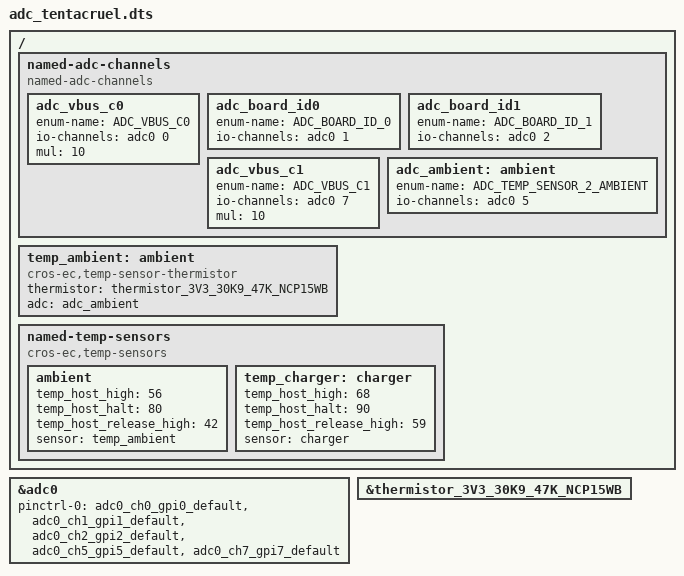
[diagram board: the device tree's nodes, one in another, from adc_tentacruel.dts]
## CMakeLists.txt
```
# Copyright 2021 The ChromiumOS Authors
# Use of this source code is governed by a BSD-style license that can be
# found in the LICENSE file.

cmake_minimum_required(VERSION 3.13.1)

find_package(Zephyr REQUIRED HINTS "${ZEPHYR_BASE}")

cros_ec_library_include_directories(include)

# Include selected EC source from the baseboard
zephyr_library_sources(
	"src/board.c"
	"src/board_chipset.c"
	"src/hibernate.c"
)

zephyr_library_sources_ifdef(CONFIG_PLATFORM_EC_USBC "src/usbc_config.c")
zephyr_library_sources_ifdef(CONFIG_PLATFORM_EC_USBC "src/usb_pd_policy.c")
zephyr_library_sources_ifdef(CONFIG_VARIANT_CORSOLA_DB_DETECTION
			     "src/variant_db_detection.c")

if(DEFINED CONFIG_BOARD_KRABBY)
	project(krabby)
	zephyr_library_sources("src/krabby/hooks.c"
			       "src/krabby/charger_workaround.c"
			       "src/krabby/ppc_krabby.c")
	zephyr_library_sources_ifdef(CONFIG_PLATFORM_EC_I2C "src/krabby/i2c.c")
	zephyr_library_sources_ifdef(CONFIG_PLATFORM_EC_USBC
				     "src/krabby/usb_pd_policy.c")
	zephyr_library_sources_ifdef(CONFIG_PLATFORM_EC_USBC
				     "src/krabby/usbc_config.c")
elseif(DEFINED CONFIG_BOARD_KINGLER)
	project(kingler)
	zephyr_library_sources_ifdef(CONFIG_PLATFORM_EC_I2C "src/kingler/i2c.c")
	zephyr_library_sources_ifdef(CONFIG_PLATFORM_EC_LED_COMMON
				     "src/kingler/led.c")
	zephyr_library_sources_ifdef(CONFIG_PLATFORM_EC_USBC
				     "src/kingler/usb_pd_policy.c")
	zephyr_library_sources_ifdef(CONFIG_PLATFORM_EC_USBC
				     "src/kingler/usbc_config.c")
	zephyr_library_sources_ifdef(CONFIG_PLATFORM_EC_BUTTONS_RUNTIME_CONFIG
				     "src/kingler/button.c")
elseif(DEFINED CONFIG_BOARD_STEELIX)
	project(steelix)
	zephyr_library_sources("src/kingler/board_steelix.c")
	zephyr_library_sources_ifdef(CONFIG_PLATFORM_EC_I2C "src/kingler/i2c.c")
	zephyr_library_sources_ifdef(CONFIG_PLATFORM_EC_LED_COMMON
				     "src/kingler/led_steelix.c")
	zephyr_library_sources_ifdef(CONFIG_PLATFORM_EC_USBC
				     "src/kingler/usb_pd_policy.c")
	zephyr_library_sources_ifdef(CONFIG_PLATFORM_EC_USBC
				     "src/kingler/usbc_config.c")

elseif(DEFINED CONFIG_BOARD_TENTACRUEL)
	project(tentacruel)
	zephyr_library_sources("src/krabby/hooks.c"
				"src/krabby/charger_workaround.c"
				"src/krabby/sensor_tentacruel.c"
				"src/krabby/temp_tentacruel.c"
				"src/krabby/ppc_tentacruel.c")
	zephyr_library_sources_ifdef(CONFIG_PLATFORM_EC_I2C "src/krabby/i2c.c")
	zephyr_library_sources_ifdef(CONFIG_PLATFORM_EC_USBC
				"src/krabby/usb_pd_policy.c")
	zephyr_library_sources_ifdef(CONFIG_PLATFORM_EC_USBC
				"src/krabby/usbc_config.c")

elseif(DEFINED CONFIG_BOARD_MAGIKARP)
	project(magikarp)
	zephyr_library_sources("src/krabby/hooks.c"
				"src/krabby/sensor_magikarp.c"
				"src/krabby/ppc_krabby.c"
				"src/krabby/keyboard_magikarp.c")
	zephyr_library_sources_ifdef(CONFIG_PLATFORM_EC_I2C "src/krabby/i2c.c")
	zephyr_library_sources_ifdef(CONFIG_PLATFORM_EC_USBC
				     "src/krabby/usb_pd_policy.c")
	zephyr_library_sources_ifdef(CONFIG_PLATFORM_EC_USBC
				     "src/krabby/usbc_config.c")

endif()
```

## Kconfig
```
# Copyright 2021 The ChromiumOS Authors
# Use of this source code is governed by a BSD-style license that can be
# found in the LICENSE file.

config BOARD_KRABBY
	bool "Google Krabby Board"
	help
	  Build Google Krabby reference board. Krabby has MediaTek MT8186 SoC
	  with ITE it81202-bx EC.

config BOARD_KINGLER
	bool "Google Kingler Board"
	help
	  Build Google Kingler reference board. Krabby has MediaTek MT8186 SoC
	  with NPCX993FA0BX EC.

config BOARD_STEELIX
	bool "Google Steelix Board"
	help
	  Build Google Steelix variant board. Steelix is a variant of Kingler
	  and has MediaTek MT8186 SoC with NPCX993FA0BX EC.

config BOARD_TENTACRUEL
	bool "Google Tentacruel Board"
	help
	  Build Google Tentacruel variant board. Tentacruel is a variant of Krabby
	  and has MediaTek MT8186 SoC with ITE it81202-bx EC.

config BOARD_MAGIKARP
	bool "Google Magikarp Board"
	help
	  Build Google Magikarp variant board. Magikarp is a variant of Krabby
	  and has MediaTek MT8186 SoC with ITE it81202-bx EC.

config VARIANT_CORSOLA_DB_DETECTION
	bool "Corsola Platform Runtime Daughter Board Detection"
	depends on PLATFORM_EC_USB_PD_TCPC_RUNTIME_CONFIG
	depends on PLATFORM_EC_USB_MUX_RUNTIME_CONFIG
	help
	  Daughter board detection for Type-C subboard or HDMI subboard. This
          includes pin configuration and driver loading.
	default y

config VARIANT_CORSOLA_USBA
	bool "Corsola Platform USB-A support"
	help
	  Support Corsola USB-A related functions. Enable this function if
	  it has USB-A ports.
        depends on PLATFORM_EC_USBC
	default y

source "Kconfig.zephyr"
```

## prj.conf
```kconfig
# Copyright 2021 The ChromiumOS Authors
# Use of this source code is governed by a BSD-style license that can be
# found in the LICENSE file.
#

# http://google3/hardware/standards/usb/
CONFIG_PLATFORM_EC_USB_PID=0x505C

# CROS EC
CONFIG_CROS_EC=y
CONFIG_PLATFORM_EC=y
CONFIG_PLATFORM_EC_SWITCH=y
CONFIG_SHIMMED_TASKS=y

# AP SoC configuration
CONFIG_AP=y
CONFIG_AP_ARM_MTK_MT8186=y

# Variant config
CONFIG_VARIANT_CORSOLA_DB_DETECTION=y

# Shell features
CONFIG_KERNEL_SHELL=y
CONFIG_SHELL_HELP=y
CONFIG_SHELL_HISTORY=y
CONFIG_SHELL_TAB=y
CONFIG_SHELL_TAB_AUTOCOMPLETION=y

# CBI
CONFIG_EEPROM=y
CONFIG_EEPROM_AT24=y
CONFIG_EEPROM_SHELL=n
CONFIG_PLATFORM_EC_BOARD_VERSION_CBI=y
CONFIG_PLATFORM_EC_CBI_EEPROM=y

# I2C
CONFIG_I2C=y

# Keyboard
CONFIG_PLATFORM_EC_KEYBOARD=y
CONFIG_PLATFORM_EC_KEYBOARD_PROTOCOL_MKBP=y
CONFIG_PLATFORM_EC_KEYBOARD_COL2_INVERTED=y

# MKBP
CONFIG_PLATFORM_EC_MKBP_EVENT=y
CONFIG_PLATFORM_EC_MKBP_INPUT_DEVICES=y
CONFIG_PLATFORM_EC_MKBP_USE_GPIO=y

# EFS2
CONFIG_PLATFORM_EC_VBOOT_EFS2=y

# USB
CONFIG_PLATFORM_EC_USB_PD_TBT_COMPAT_MODE=n
CONFIG_PLATFORM_EC_USB_PD_USB32_DRD=n
CONFIG_PLATFORM_EC_USB_PD_USB4=n
CONFIG_PLATFORM_EC_USB_PORT_POWER_DUMB_CUSTOM_HOOK=y

# USB-C
CONFIG_PLATFORM_EC_USBC=y
CONFIG_PLATFORM_EC_USBC_SS_MUX_DFP_ONLY=y
CONFIG_PLATFORM_EC_USB_PD_DPS=y
CONFIG_PLATFORM_EC_USB_PD_DP_HPD_GPIO=y
CONFIG_PLATFORM_EC_USB_PD_DP_HPD_GPIO_CUSTOM=y
CONFIG_PLATFORM_EC_USB_PD_FRS=y

# Power Seq
CONFIG_PLATFORM_EC_CHIPSET_RESUME_INIT_HOOK=y
CONFIG_PLATFORM_EC_EXTPOWER_GPIO=y
CONFIG_PLATFORM_EC_POWERSEQ=y
CONFIG_PLATFORM_EC_POWERSEQ_HOST_SLEEP=y
CONFIG_PLATFORM_EC_POWERSEQ_PP5000_CONTROL=n
CONFIG_PLATFORM_EC_POWER_SLEEP_FAILURE_DETECTION=y

# Optional features
CONFIG_FLASH_SHELL=n

# EEPROM
CONFIG_PLATFORM_EC_EEPROM_CBI_WP=y

# Host Commands
CONFIG_PLATFORM_EC_HOSTCMD=y

# Battery
CONFIG_PLATFORM_EC_BATTERY=y
CONFIG_PLATFORM_EC_BATTERY_CUT_OFF=y
CONFIG_PLATFORM_EC_BATTERY_FUEL_GAUGE=y
CONFIG_PLATFORM_EC_BATTERY_PRESENT_GPIO=y
CONFIG_PLATFORM_EC_BATTERY_SMART=y
CONFIG_PLATFORM_EC_I2C_PASSTHRU_RESTRICTED=y
CONFIG_PLATFORM_EC_I2C_VIRTUAL_BATTERY=y

# Charger
CONFIG_PLATFORM_EC_BC12_CLIENT_MODE_ONLY_PI3USB9201=y
CONFIG_PLATFORM_EC_CHARGER=y
CONFIG_PLATFORM_EC_CHARGE_MANAGER=y

# Button
CONFIG_PLATFORM_EC_CMD_BUTTON=y
CONFIG_PLATFORM_EC_POWER_BUTTON=y
CONFIG_PLATFORM_EC_VOLUME_BUTTONS=y
```

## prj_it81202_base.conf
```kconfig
# Copyright 2022 The ChromiumOS Authors
# Use of this source code is governed by a BSD-style license that can be
# found in the LICENSE file.

# Bring up options
CONFIG_SHELL_HISTORY_BUFFER=256
CONFIG_PLATFORM_EC_SYSTEM_UNLOCKED=y
CONFIG_PLATFORM_EC_BRINGUP=y

# Power Sequencing
CONFIG_PLATFORM_EC_CHIPSET_RESET_HOOK=y

# Lid Switch
CONFIG_PLATFORM_EC_LID_SWITCH=y

# Charger
CONFIG_PLATFORM_EC_CHARGE_RAMP_HW=y
CONFIG_PLATFORM_EC_CHARGER_DISCHARGE_ON_AC=y
CONFIG_PLATFORM_EC_CHARGER_DISCHARGE_ON_AC_CHARGER=y
CONFIG_PLATFORM_EC_CHARGER_RT9490=y
CONFIG_PLATFORM_EC_CHARGER_MAINTAIN_VBAT=y
CONFIG_PLATFORM_EC_CHARGER_PSYS=y
CONFIG_PLATFORM_EC_CHARGER_PSYS_READ=y
# BOARD_RS2
CONFIG_PLATFORM_EC_CHARGER_SENSE_RESISTOR=10
# BOARD_RS1
CONFIG_PLATFORM_EC_CHARGER_SENSE_RESISTOR_AC=20
CONFIG_PLATFORM_EC_CONSOLE_CMD_CHARGER_DUMP=y

# Host Commands
CONFIG_PLATFORM_EC_CONSOLE_CMD_ACCELS=y
CONFIG_PLATFORM_EC_CONSOLE_CMD_ACCEL_INFO=y
CONFIG_PLATFORM_EC_CONSOLE_CMD_CHARGER_ADC_AMON_BMON=y
CONFIG_PLATFORM_EC_CONSOLE_CMD_SYSINFO=y
CONFIG_PLATFORM_EC_HOST_COMMAND_STATUS=y

# LED
CONFIG_PLATFORM_EC_LED_DT=y

# PWM
CONFIG_PWM=y
CONFIG_PWM_SHELL=n

# Sensors
CONFIG_PLATFORM_EC_MOTIONSENSE=y
CONFIG_PLATFORM_EC_ACCEL_FIFO=y
CONFIG_PLATFORM_EC_GMR_TABLET_MODE=y
CONFIG_PLATFORM_EC_LID_ANGLE=y
CONFIG_PLATFORM_EC_LID_ANGLE_UPDATE=y
CONFIG_PLATFORM_EC_SENSOR_TIGHT_TIMESTAMPS=y
CONFIG_PLATFORM_EC_TABLET_MODE=y
CONFIG_PLATFORM_EC_TABLET_MODE_SWITCH=y
CONFIG_PLATFORM_EC_MAX_SENSOR_FREQ_MILLIHZ=100000

# Sensor Drivers
CONFIG_PLATFORM_EC_ACCEL_LIS2DW12=y
CONFIG_PLATFORM_EC_ACCELGYRO_ICM42607=y
CONFIG_PLATFORM_EC_ACCELGYRO_ICM_COMM_I2C=y

# Tasks
CONFIG_TASK_CHARGER_STACK_SIZE=1024
CONFIG_TASK_CHIPSET_STACK_SIZE=1440
CONFIG_TASK_MOTIONSENSE_STACK_SIZE=1024
CONFIG_TASK_PD_STACK_SIZE=1280

# USB-A
CONFIG_PLATFORM_EC_USBA=y

# USB-C
CONFIG_PLATFORM_EC_BC12_SINGLE_DRIVER=n
CONFIG_PLATFORM_EC_USBC_PPC_RT1739=y
CONFIG_PLATFORM_EC_USBC_PPC_SYV682C=y
CONFIG_PLATFORM_EC_USBC_PPC_SYV682X=y
CONFIG_PLATFORM_EC_USB_MUX_IT5205=y
CONFIG_PLATFORM_EC_USB_MUX_TUSB546=y
CONFIG_PLATFORM_EC_USB_MUX_VIRTUAL=y
CONFIG_PLATFORM_EC_USB_PD_DISCHARGE_PPC=y
CONFIG_PLATFORM_EC_USB_PD_FRS_PPC=y
CONFIG_PLATFORM_EC_USB_PD_LOGGING=y
CONFIG_PLATFORM_EC_USB_PD_TCPM_DRIVER_IT8XXX2=y
CONFIG_PLATFORM_EC_USB_PD_TCPM_ITE_ON_CHIP=y
CONFIG_PLATFORM_EC_USB_PD_TCPM_TCPCI=y
CONFIG_PLATFORM_EC_USB_PD_VBUS_DETECT_PPC=y
CONFIG_PLATFORM_EC_USB_PD_VBUS_MEASURE_ADC_EACH_PORT=y
CONFIG_PLATFORM_EC_USB_PD_DUAL_ROLE_AUTO_TOGGLE=n
CONFIG_PLATFORM_EC_CONFIG_USB_PD_3A_PORTS=0
CONFIG_PLATFORM_EC_USB_PD_PULLUP=1

CONFIG_PLATFORM_EC_SHA256_UNROLLED=y

# TODO(b/180980668): bring these features up
CONFIG_LTO=n
CONFIG_PLATFORM_EC_BACKLIGHT_LID=n
```

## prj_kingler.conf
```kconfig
# Copyright 2021 The Chromium OS Authors. All rights reserved.
# Use of this source code is governed by a BSD-style license that can be
# found in the LICENSE file.

# Variant config
CONFIG_BOARD_KINGLER=y

# LED
CONFIG_PLATFORM_EC_LED_PWM=y

# Keyboard
CONFIG_PLATFORM_EC_KEYBOARD_PWRBTN_ASSERTS_KSI2=y
```

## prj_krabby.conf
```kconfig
# Copyright 2021 The Chromium OS Authors.
# Use of this source code is governed by a BSD-style license that can be
# found in the LICENSE file.

# Variant config
CONFIG_BOARD_KRABBY=y

# Keyboard
CONFIG_PLATFORM_EC_KEYBOARD_PWRBTN_ASSERTS_KSI2=y
```

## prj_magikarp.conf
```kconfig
# Copyright 2022 The ChromiumOS Authors
# Use of this source code is governed by a BSD-style license that can be
# found in the LICENSE file.

# Variant config
CONFIG_BOARD_MAGIKARP=y

# USB-C
CONFIG_PLATFORM_EC_BC12_DETECT_PI3USB9201=y
CONFIG_PLATFORM_EC_USB_MUX_TUSB546=n
CONFIG_PLATFORM_EC_USB_MUX_PS8743=y
CONFIG_PLATFORM_EC_PD_MAX_POWER_MW=45000

# Keyboard
CONFIG_PLATFORM_EC_KEYBOARD_REFRESH_ROW3=y
CONFIG_PLATFORM_EC_KEYBOARD_PWRBTN_ASSERTS_KSI3=y

# Sensor
CONFIG_PLATFORM_EC_ACCELGYRO_BMI3XX=y
CONFIG_PLATFORM_EC_ACCELGYRO_BMI_COMM_I2C=y

# Temperature sensors
CONFIG_PLATFORM_EC_TEMP_SENSOR=y
CONFIG_PLATFORM_EC_THERMISTOR=y

# Battery
CONFIG_PLATFORM_EC_BATTERY_REVIVE_DISCONNECT=y
```

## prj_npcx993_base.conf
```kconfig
# Copyright 2022 The ChromiumOS Authors.
# Use of this source code is governed by a BSD-style license that can be
# found in the LICENSE file.


# Bring up options
CONFIG_PLATFORM_EC_SYSTEM_UNLOCKED=y

# Debug options and features; can be disabled to save memory or once bringup
# is complete.
CONFIG_SHELL_MINIMAL=n
CONFIG_LOG=y
CONFIG_LOG_MODE_MINIMAL=y

# ADC
CONFIG_ADC=y

# Charger
CONFIG_PLATFORM_EC_CHARGER_DISCHARGE_ON_AC=y
CONFIG_PLATFORM_EC_CHARGER_ISL9238C=y
CONFIG_PLATFORM_EC_CHARGER_PSYS=y
CONFIG_PLATFORM_EC_CHARGER_PSYS_READ=y
CONFIG_PLATFORM_EC_CHARGER_SENSE_RESISTOR=10
CONFIG_PLATFORM_EC_CHARGER_SENSE_RESISTOR_AC=20
CONFIG_PLATFORM_EC_CONSOLE_CMD_CHARGER_ADC_AMON_BMON=y

# PWM
CONFIG_PWM=y
CONFIG_PWM_SHELL=n

# LED
CONFIG_PLATFORM_EC_LED_COMMON=y
CONFIG_PLATFORM_EC_LED_ONOFF_STATES=y

# Math
CONFIG_PLATFORM_EC_MATH_UTIL=y

# Power sequencing
CONFIG_PLATFORM_EC_POWERSEQ_MT8186=y
CONFIG_PLATFORM_EC_POWERSEQ_S4=n

# Button
CONFIG_PLATFORM_EC_BUTTONS_RUNTIME_CONFIG=y

# Sensors
CONFIG_PLATFORM_EC_ACCELGYRO_BMI3XX=y
CONFIG_PLATFORM_EC_ACCELGYRO_BMI_COMM_I2C=y
CONFIG_PLATFORM_EC_ACCEL_BMA4XX=y
CONFIG_PLATFORM_EC_ACCEL_FIFO=y
CONFIG_PLATFORM_EC_CONSOLE_CMD_ACCELS=y
CONFIG_PLATFORM_EC_CONSOLE_CMD_ACCEL_INFO=y
CONFIG_PLATFORM_EC_GMR_TABLET_MODE=y
CONFIG_PLATFORM_EC_LID_ANGLE=y
CONFIG_PLATFORM_EC_LID_ANGLE_UPDATE=y
CONFIG_PLATFORM_EC_LID_SWITCH=y
CONFIG_PLATFORM_EC_MOTIONSENSE=y
CONFIG_PLATFORM_EC_SENSOR_TIGHT_TIMESTAMPS=y
CONFIG_PLATFORM_EC_TABLET_MODE=y
CONFIG_PLATFORM_EC_TABLET_MODE_SWITCH=y

# USBA
CONFIG_PLATFORM_EC_USBA=y

# USBC
CONFIG_PLATFORM_EC_BC12_DETECT_PI3USB9201=y
CONFIG_PLATFORM_EC_BC12_SINGLE_DRIVER=n
CONFIG_PLATFORM_EC_PD_POWER_SUPPLY_TURN_OFF_DELAY=15000
CONFIG_PLATFORM_EC_PD_POWER_SUPPLY_TURN_ON_DELAY=15000
CONFIG_PLATFORM_EC_USBC_PPC=y
CONFIG_PLATFORM_EC_USBC_PPC_NX20P3483=y
CONFIG_PLATFORM_EC_USBC_PPC_RT1718S=y
CONFIG_PLATFORM_EC_USB_MUX_PS8743=y
CONFIG_PLATFORM_EC_USB_MUX_VIRTUAL=y
CONFIG_PLATFORM_EC_USB_PD_DISCHARGE_PPC=y
CONFIG_PLATFORM_EC_USB_PD_FRS_TCPC=y
CONFIG_PLATFORM_EC_USB_PD_LOGGING=y
CONFIG_PLATFORM_EC_USB_PD_DEBUG_FIXED_LEVEL=y
CONFIG_PLATFORM_EC_USB_PD_DEBUG_LEVEL=2
CONFIG_PLATFORM_EC_USB_PD_TCPM_ANX7447=y
CONFIG_PLATFORM_EC_USB_PD_TCPM_ANX7447_AUX_PU_PD=y
CONFIG_PLATFORM_EC_USB_PD_TCPM_RT1718S=y
CONFIG_PLATFORM_EC_USB_PD_TCPM_SBU=y
CONFIG_PLATFORM_EC_USB_PD_VBUS_DETECT_TCPC=y
CONFIG_PLATFORM_EC_USB_PD_VBUS_MEASURE_BY_BOARD=y

# External power
CONFIG_PLATFORM_EC_BACKLIGHT_LID=n

# Keyboard
CONFIG_CROS_KB_RAW_NPCX=y
CONFIG_CROS_KB_RAW_NPCX_KSO_HIGH_DRIVE=y

CONFIG_SYSCON=y

CONFIG_PLATFORM_EC_BOARD_VERSION_GPIO=n
```

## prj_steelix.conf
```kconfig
# Copyright 2022 The ChromiumOS Authors
# Use of this source code is governed by a BSD-style license that can be
# found in the LICENSE file.

# Variant config
CONFIG_BOARD_STEELIX=y

# steelix only use D2, drop the workaround config for H1
CONFIG_PLATFORM_EC_BOARD_RESET_AFTER_POWER_ON=n

# Motion sensor
CONFIG_PLATFORM_EC_ACCEL_LIS2DW12=y
CONFIG_PLATFORM_EC_ACCELGYRO_LSM6DSM=y
CONFIG_PLATFORM_EC_DYNAMIC_MOTION_SENSOR_COUNT=y

# Keyboard
CONFIG_PLATFORM_EC_KEYBOARD_REFRESH_ROW3=y
CONFIG_PLATFORM_EC_KEYBOARD_PWRBTN_ASSERTS_KSI3=y
CONFIG_PLATFORM_EC_KEYBOARD_STRICT_DEBOUNCE=y

# USBC
CONFIG_PLATFORM_EC_PD_MAX_CURRENT_MA=3250
CONFIG_PLATFORM_EC_PD_MAX_POWER_MW=65000

# Remove bring up options for FW QUAL
CONFIG_PLATFORM_EC_SYSTEM_UNLOCKED=n

# Remove debug options and features for FW QUAL
CONFIG_LOG=n
CONFIG_LOG_MODE_MINIMAL=n
CONFIG_SHELL_MINIMAL=y
CONFIG_PLATFORM_EC_USB_PD_DEBUG_LEVEL=0

# AC_OK debounce time
CONFIG_PLATFORM_EC_EXTPOWER_DEBOUNCE_MS=800
```

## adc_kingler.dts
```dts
/* Copyright 2022 The ChromiumOS Authors
 * Use of this source code is governed by a BSD-style license that can be
 * found in the LICENSE file.
 */

/*
 * Kingler and Steelix use the same dts, take care of this when modify it.
 */

/ {
	named-adc-channels {
		compatible = "named-adc-channels";

		adc_charger_pmon_r {
			enum-name = "ADC_PSYS";
			io-channels = <&adc0 0>;
			/*
			 * ISL9238C PSYS output is 1.44 uA/W over 33K resistor.
			 */
			mul = <21043>;
		};
		adc_ec_id0 {
			enum-name = "ADC_ID_0";
			io-channels = <&adc0 1>;
		};
		adc_ec_id1 {
			enum-name = "ADC_ID_1";
			io-channels = <&adc0 2>;
		};
		adc_charger_amon_r {
			enum-name = "ADC_AMON_BMON";
			io-channels = <&adc0 3>;
			mul = <1000>;
			div = <18>;
		};
	};
};

&adc0 {
	status = "okay";
	pinctrl-0 = <&adc0_chan0_gp45
		     &adc0_chan1_gp44
		     &adc0_chan2_gp43
		     &adc0_chan3_gp42>;
	pinctrl-names = "default";
};
```

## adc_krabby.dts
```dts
/* Copyright 2021 The Chromium OS Authors. All rights reserved.
 * Use of this source code is governed by a BSD-style license that can be
 * found in the LICENSE file.
 */

/ {
	named-adc-channels {
		compatible = "named-adc-channels";

		adc_vbus_c0 {
			enum-name = "ADC_VBUS_C0";
			io-channels = <&adc0 0>;
			mul = <10>;
		};
		adc_board_id0 {
			enum-name = "ADC_BOARD_ID_0";
			io-channels = <&adc0 1>;
		};
		adc_board_id1 {
			enum-name = "ADC_BOARD_ID_1";
			io-channels = <&adc0 2>;
		};
		adc_vbus_c1 {
			enum-name = "ADC_VBUS_C1";
			io-channels = <&adc0 7>;
			mul = <10>;
		};
	};
};

&adc0 {
	status = "okay";
	pinctrl-0 = <&adc0_ch0_gpi0_default
		     &adc0_ch1_gpi1_default
		     &adc0_ch2_gpi2_default
		     &adc0_ch7_gpi7_default>;
	pinctrl-names = "default";
};
```

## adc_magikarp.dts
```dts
/* Copyright 2022 The ChromiumOS Authors
 * Use of this source code is governed by a BSD-style license that can be
 * found in the LICENSE file.
 */

#include <cros/thermistor/thermistor.dtsi>

/ {
	named-adc-channels {
		compatible = "named-adc-channels";
		adc_vbus_c0 {
			enum-name = "ADC_VBUS_C0";
			io-channels = <&adc0 0>;
			mul = <10>;
		};
		adc_board_id0 {
			enum-name = "ADC_BOARD_ID_0";
			io-channels = <&adc0 1>;
		};
		adc_board_id1 {
			enum-name = "ADC_BOARD_ID_1";
			io-channels = <&adc0 2>;
		};
		adc_vbus_c1 {
			enum-name = "ADC_VBUS_C1";
			io-channels = <&adc0 7>;
			mul = <10>;
		};
		adc_ambient: ambient {
			enum-name = "ADC_TEMP_SENSOR_2_AMBIENT";
			io-channels = <&adc0 5>;
		};
	};
};

&adc0 {
	status = "okay";
	pinctrl-0 = <&adc0_ch0_gpi0_default
		     &adc0_ch1_gpi1_default
		     &adc0_ch2_gpi2_default
		     &adc0_ch5_gpi5_default
		     &adc0_ch7_gpi7_default>;
	pinctrl-names = "default";
};

/ {
	named-temp-sensors {
		ambient {
			compatible = "cros-ec,temp-sensor-thermistor",
				     "cros-ec,temp-sensor";
			thermistor = <&thermistor_3V3_30K9_47K_NCP15WB>;
			enum-name = "TEMP_SENSOR_AMB";
			adc = <&adc_ambient>;
		};
	};
};

&thermistor_3V3_30K9_47K_NCP15WB {
	status = "okay";
};
```

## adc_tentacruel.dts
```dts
/* Copyright 2022 The ChromiumOS Authors
 * Use of this source code is governed by a BSD-style license that can be
 * found in the LICENSE file.
 */

#include <cros/thermistor/thermistor.dtsi>

/ {
	named-adc-channels {
		compatible = "named-adc-channels";
		adc_vbus_c0 {
			enum-name = "ADC_VBUS_C0";
			io-channels = <&adc0 0>;
			mul = <10>;
		};
		adc_board_id0 {
			enum-name = "ADC_BOARD_ID_0";
			io-channels = <&adc0 1>;
		};
		adc_board_id1 {
			enum-name = "ADC_BOARD_ID_1";
			io-channels = <&adc0 2>;
		};
		adc_vbus_c1 {
			enum-name = "ADC_VBUS_C1";
			io-channels = <&adc0 7>;
			mul = <10>;
		};
		adc_ambient: ambient {
			enum-name = "ADC_TEMP_SENSOR_2_AMBIENT";
			io-channels = <&adc0 5>;
		};
	};
};

&adc0 {
	status = "okay";
	pinctrl-0 = <&adc0_ch0_gpi0_default
		     &adc0_ch1_gpi1_default
		     &adc0_ch2_gpi2_default
		     &adc0_ch5_gpi5_default
		     &adc0_ch7_gpi7_default>;
	pinctrl-names = "default";
};

/ {
	temp_ambient: ambient {
		compatible = "cros-ec,temp-sensor-thermistor";
		thermistor = <&thermistor_3V3_30K9_47K_NCP15WB>;
		adc = <&adc_ambient>;
	};

	named-temp-sensors {
		compatible = "cros-ec,temp-sensors";
		ambient {
			temp_host_high = <56>;
			temp_host_halt = <80>;
			temp_host_release_high = <42>;
			sensor = <&temp_ambient>;
		};
		temp_charger: charger {
			temp_host_high = <68>;
			temp_host_halt = <90>;
			temp_host_release_high = <59>;
			sensor = <&charger>;
		};
	};
};

&thermistor_3V3_30K9_47K_NCP15WB {
	status = "okay";
};
```

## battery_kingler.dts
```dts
/* Copyright 2021 The Chromium OS Authors. All rights reserved.
 * Use of this source code is governed by a BSD-style license that can be
 * found in the LICENSE file.
 */

/ {
	batteries {
		default_battery: smp_l20m3pg2 {
			compatible = "smp,l20m3pg2";
		};
		lgc_l20l3pg2 {
			compatible = "lgc,l20l3pg2";
		};
	};
};
```

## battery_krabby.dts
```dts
/* Copyright 2021 The ChromiumOS Authors
 * Use of this source code is governed by a BSD-style license that can be
 * found in the LICENSE file.
 */

/ {
	batteries {
		default_battery: c235 {
			compatible = "celxpert,c235-41", "battery-smart";
		};
	};
};
```

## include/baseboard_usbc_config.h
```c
/* Copyright 2021 The ChromiumOS Authors
 * Use of this source code is governed by a BSD-style license that can be
 * found in the LICENSE file.
 */

/* Corsola daughter board detection */

#ifndef __CROS_EC_BASEBOARD_USBC_CONFIG_H
#define __CROS_EC_BASEBOARD_USBC_CONFIG_H

#include "gpio.h"

#ifdef CONFIG_PLATFORM_EC_USB_PD_TCPM_RT1718S
#define GPIO_EN_USB_C1_SINK RT1718S_GPIO1
#define GPIO_EN_USB_C1_SOURCE RT1718S_GPIO2
#define GPIO_EN_USB_C1_FRS RT1718S_GPIO3
#endif

void ppc_interrupt(enum gpio_signal signal);
void ccd_interrupt(enum gpio_signal signal);
void hdmi_hpd_interrupt(enum gpio_signal signal);
void ps185_hdmi_hpd_mux_set(void);
int corsola_is_dp_muxable(int port);

/* USB-A ports */
enum usba_port { USBA_PORT_A0 = 0, USBA_PORT_COUNT };

/* USB-C ports */
enum usbc_port { USBC_PORT_C0 = 0, USBC_PORT_C1, USBC_PORT_COUNT };
BUILD_ASSERT(USBC_PORT_COUNT == CONFIG_USB_PD_PORT_MAX_COUNT);

/**
 * Is the port fine to be muxed its DisplayPort lines?
 *
 * Only one port can be muxed to DisplayPort at a time.
 *
 * @param port	Port number of TCPC.
 * @return	1 is fine; 0 is bad as other port is already muxed;
 */
int corsola_is_dp_muxable(int port);

#endif /* __CROS_EC_BASEBOARD_USBC_CONFIG_H */
```

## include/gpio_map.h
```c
/* Copyright 2021 The Chromium OS Authors. All rights reserved.
 * Use of this source code is governed by a BSD-style license that can be
 * found in the LICENSE file.
 */

#ifndef __ZEPHYR_GPIO_MAP_H
#define __ZEPHYR_GPIO_MAP_H

#include <zephyr/devicetree.h>
#include <gpio_signal.h>

#define GPIO_ENTERING_RW GPIO_UNIMPLEMENTED

#ifdef CONFIG_PLATFORM_EC_USB_PD_TCPM_RT1718S
#define GPIO_EN_USB_C1_SINK RT1718S_GPIO1
#define GPIO_EN_USB_C1_SOURCE RT1718S_GPIO2
#define GPIO_EN_USB_C1_FRS RT1718S_GPIO3
#endif

#endif /* __ZEPHYR_GPIO_MAP_H */
```

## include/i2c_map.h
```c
/* Copyright 2021 The Chromium OS Authors. All rights reserved.
 * Use of this source code is governed by a BSD-style license that can be
 * found in the LICENSE file.
 */

#ifndef __ZEPHYR_I2C_MAP_H
#define __ZEPHYR_I2C_MAP_H

#include <zephyr/devicetree.h>

#include "i2c/i2c.h"

#endif /* __ZEPHYR_I2C_MAP_H */
```

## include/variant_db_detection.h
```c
/* Copyright 2021 The ChromiumOS Authors
 * Use of this source code is governed by a BSD-style license that can be
 * found in the LICENSE file.
 */

/* Corsola daughter board detection */

#ifndef __CROS_EC_CORSOLA_DB_DETECTION_H
#define __CROS_EC_CORSOLA_DB_DETECTION_H

enum corsola_db_type {
	CORSOLA_DB_UNINIT = -1,
	CORSOLA_DB_NONE,
	CORSOLA_DB_TYPEC,
	CORSOLA_DB_HDMI,
	CORSOLA_DB_COUNT,
};

#ifdef CONFIG_VARIANT_CORSOLA_DB_DETECTION
/*
 * Get the connected daughterboard type.
 *
 * @return		The daughterboard type.
 */
enum corsola_db_type corsola_get_db_type(void);
#else
inline enum corsola_db_type corsola_get_db_type(void)
{
	return CORSOLA_DB_NONE;
};
#endif /* CONFIG_VARIANT_CORSOLA_DB_DETECTION */

/* return the adjusted port count for board overridden usbc/charger functions.
 */
uint8_t board_get_adjusted_usb_pd_port_count(void);

#endif /* __CROS_EC_CORSOLA_DB_DETECTION_H */
```

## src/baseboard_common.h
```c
/* Copyright 2021 The Chromium OS Authors. All rights reserved.
 * Use of this source code is governed by a BSD-style license that can be
 * found in the LICENSE file.
 */

/* Corsola baseboard-specific onfiguration common to ECOS and Zephyr */

#ifndef __CROS_EC_BASEBOARD_COMMON_H
#define __CROS_EC_BASEBOARD_COMMON_H

#ifndef __ASSEMBLER__

#include "gpio_signal.h"

/**
 * board_get_version() - Get the board version
 *
 * Read the ADC to obtain the board version
 *
 * @return board version in the range 0 to 14 inclusive
 */
int board_get_version(void);

void ppc_interrupt(enum gpio_signal signal);
void bc12_interrupt(enum gpio_signal signal);
void x_ec_interrupt(enum gpio_signal signal);

#endif /* !__ASSEMBLER__ */
#endif /* __CROS_EC_BASEBOARD_COMMON_H */
```

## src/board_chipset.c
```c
/* Copyright 2021 The ChromiumOS Authors
 * Use of this source code is governed by a BSD-style license that can be
 * found in the LICENSE file.
 */

/* Corsola baseboard-chipset specific configuration */

#include <zephyr/init.h>
#include <ap_power/ap_power.h>
#include <zephyr/drivers/gpio.h>
#include "gpio.h"

static void board_backlight_handler(struct ap_power_ev_callback *cb,
				    struct ap_power_ev_data data)
{
	int value;

	switch (data.event) {
	default:
		return;

	case AP_POWER_RESUME:
		/* Called on AP S3 -> S0 transition */
		value = 1;
		break;

	case AP_POWER_SUSPEND:
		/* Called on AP S0 -> S3 transition */
		value = 0;
		break;
	}
	gpio_pin_set_dt(GPIO_DT_FROM_NODELABEL(gpio_ec_bl_en_od), value);
}

static int install_backlight_handler(const struct device *unused)
{
	static struct ap_power_ev_callback cb;

	/*
	 * Add a callback for suspend/resume to
	 * control the keyboard backlight.
	 */
	ap_power_ev_init_callback(&cb, board_backlight_handler,
				  AP_POWER_RESUME | AP_POWER_SUSPEND);
	ap_power_ev_add_callback(&cb);
	return 0;
}

SYS_INIT(install_backlight_handler, APPLICATION, 1);
```

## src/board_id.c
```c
/* Copyright 2021 The Chromium OS Authors. All rights reserved.
 * Use of this source code is governed by a BSD-style license that can be
 * found in the LICENSE file.
 */

#include "adc.h"
#include "common.h"
#include "console.h"
#include "gpio.h"
#include "hooks.h"
#include "timer.h"
#include "util.h"

/**
 * Conversion based on following table:
 *
 * ID | Rp   | Rd   | Voltage
 *    | kOhm | kOhm | mV
 * ---+------+------+--------
 *  0 | 51.1 |  2.2 | 136.2
 *  1 | 51.1 | 6.81 | 388.1
 *  2 | 51.1 |   11 | 584.5
 *  3 | 57.6 |   18 | 785.7
 *  4 | 51.1 |   22 | 993.2
 *  5 | 51.1 |   30 | 1220.7
 *  6 | 51.1 | 39.2 | 1432.6
 *  7 |   56 |   56 | 1650.0
 *  8 |   47 | 61.9 | 1875.8
 *  9 |   47 | 80.6 | 2084.5
 * 10 |   56 |  124 | 2273.3
 * 11 | 51.1 |  150 | 2461.5
 * 12 |   47 |  200 | 2672.1
 * 13 |   47 |  330 | 2888.6
 * 14 |   47 |  680 | 3086.7
 */
const static int voltage_map[] = {
	136,
	388,
	584,
	785,
	993,
	1220,
	1432,
	1650,
	1875,
	2084,
	2273,
	2461,
	2672,
	2888,
	3086,
};

const int threshold_mv = 100;

/**
 * Convert ADC value to board id using the voltage table above.
 *
 * @param ch	ADC channel to read, usually ADC_BOARD_ID_0 or ADC_BOARD_ID_1.
 *
 * @return	a non-negative board id, or negative value if error.
 */
static int adc_value_to_numeric_id(enum adc_channel ch)
{
	int mv;

	gpio_set_level(GPIO_EN_EC_ID_ODL, 0);
	/* Wait to allow cap charge */
	msleep(10);

	mv = adc_read_channel(ch);
	if (mv == ADC_READ_ERROR)
		mv = adc_read_channel(ch);

	gpio_set_level(GPIO_EN_EC_ID_ODL, 1);

	if (mv == ADC_READ_ERROR)
		return -EC_ERROR_UNKNOWN;

	for (int i = 0; i < ARRAY_SIZE(voltage_map); i++) {
		if (IN_RANGE(mv, voltage_map[i] - threshold_mv,
			     voltage_map[i] + threshold_mv))
			return i;
	}

	return -EC_ERROR_UNKNOWN;
}

static int version = -1;

/* b/163963220: Cache ADC value before board_hibernate_late() reads it */
static void board_version_init(void)
{
	version = adc_value_to_numeric_id(ADC_BOARD_ID_0);
	if (version < 0) {
		ccprints("WARN:BOARD_ID_0");
		ccprints("Assuming board id = 0");

		version = 0;
	}
}
DECLARE_HOOK(HOOK_INIT, board_version_init, HOOK_PRIO_INIT_ADC + 1);

__override int board_get_version(void)
{
	return version;
}
```

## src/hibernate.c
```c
/* Copyright 2021 The Chromium OS Authors. All rights reserved.
 * Use of this source code is governed by a BSD-style license that can be
 * found in the LICENSE file.
 */
#include <zephyr/drivers/gpio.h>

#include "charger.h"
#include "driver/charger/isl923x_public.h"
#include "system.h"

/* Corsola board specific hibernate implementation */
__override void board_hibernate(void)
{
#ifdef CONFIG_CHARGER_ISL9238C
	isl9238c_hibernate(CHARGER_SOLO);
#endif
}

__override void board_hibernate_late(void)
{
	gpio_pin_set_dt(GPIO_DT_FROM_NODELABEL(gpio_en_ulp), 1);
}
```

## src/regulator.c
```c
/* Copyright 2021 The Chromium OS Authors. All rights reserved.
 * Use of this source code is governed by a BSD-style license that can be
 * found in the LICENSE file.
 */

#include "common.h"
#include "bc12/mt6360_public.h"

/* SD Card */
int board_regulator_get_info(uint32_t index, char *name, uint16_t *num_voltages,
			     uint16_t *voltages_mv)
{
	enum mt6360_regulator_id id = index;

	return mt6360_regulator_get_info(id, name, num_voltages, voltages_mv);
}

int board_regulator_enable(uint32_t index, uint8_t enable)
{
	enum mt6360_regulator_id id = index;

	return mt6360_regulator_enable(id, enable);
}

int board_regulator_is_enabled(uint32_t index, uint8_t *enabled)
{
	enum mt6360_regulator_id id = index;

	return mt6360_regulator_is_enabled(id, enabled);
}

int board_regulator_set_voltage(uint32_t index, uint32_t min_mv,
				uint32_t max_mv)
{
	enum mt6360_regulator_id id = index;

	return mt6360_regulator_set_voltage(id, min_mv, max_mv);
}

int board_regulator_get_voltage(uint32_t index, uint32_t *voltage_mv)
{
	enum mt6360_regulator_id id = index;

	return mt6360_regulator_get_voltage(id, voltage_mv);
}
```

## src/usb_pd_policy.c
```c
/* Copyright 2021 The ChromiumOS Authors
 * Use of this source code is governed by a BSD-style license that can be
 * found in the LICENSE file.
 */

#include "atomic.h"
#include "console.h"
#include "chipset.h"
#include "hooks.h"
#include "timer.h"
#include "typec_control.h"
#include "usb_dp_alt_mode.h"
#include "usb_mux.h"
#include "usb_pd.h"
#include "usbc_ppc.h"

#include "baseboard_usbc_config.h"

#if CONFIG_USB_PD_3A_PORTS != 1
#error Corsola reference must have at least one 3.0 A port
#endif

#define CPRINTS(format, args...) cprints(CC_USBPD, format, ##args)
#define CPRINTF(format, args...) cprintf(CC_USBPD, format, ##args)

static int active_aux_port = -1;

int pd_check_vconn_swap(int port)
{
	/* Allow Vconn swap if AP is on. */
	return chipset_in_state(CHIPSET_STATE_SUSPEND | CHIPSET_STATE_ON);
}

static void set_dp_aux_path_sel(int port)
{
	gpio_pin_set_dt(GPIO_DT_FROM_NODELABEL(dp_aux_path_sel), port);
	CPRINTS("Set DP_AUX_PATH_SEL: %d", port);
}

int svdm_get_hpd_gpio(int port)
{
	/* HPD is low active, inverse the result */
	return !gpio_pin_get_dt(GPIO_DT_FROM_NODELABEL(ec_ap_dp_hpd_odl));
}

static void reset_aux_deferred(void)
{
	if (active_aux_port == -1)
		/* reset to 1 for lower power consumption. */
		set_dp_aux_path_sel(1);
}
DECLARE_DEFERRED(reset_aux_deferred);

void svdm_set_hpd_gpio(int port, int en)
{
	/*
	 * HPD is low active, inverse the en.
	 *
	 * Implement FCFS policy:
	 * 1) Enable hpd if no active port.
	 * 2) Disable hpd if active port is the given port.
	 */
	if (en && active_aux_port < 0) {
		gpio_pin_set_dt(GPIO_DT_FROM_NODELABEL(ec_ap_dp_hpd_odl), 0);
		active_aux_port = port;
		hook_call_deferred(&reset_aux_deferred_data, -1);
	}

	if (!en && active_aux_port == port) {
		gpio_pin_set_dt(GPIO_DT_FROM_NODELABEL(ec_ap_dp_hpd_odl), 1);
		active_aux_port = -1;
		/*
		 * This might be a HPD debounce to send a HPD IRQ (500us), so
		 * do not reset the aux path immediately. Defer this call and
		 * re-check if this is a real disable.
		 */
		hook_call_deferred(&reset_aux_deferred_data, 1 * MSEC);
	}
}

__override int svdm_dp_config(int port, uint32_t *payload)
{
	int opos = pd_alt_mode(port, TCPCI_MSG_SOP, USB_SID_DISPLAYPORT);
	uint8_t pin_mode = get_dp_pin_mode(port);
	mux_state_t mux_mode = svdm_dp_get_mux_mode(port);
	int mf_pref = PD_VDO_DPSTS_MF_PREF(dp_status[port]);

	if (!pin_mode) {
		return 0;
	}

	CPRINTS("pin_mode: %x, mf: %d, mux: %d", pin_mode, mf_pref, mux_mode);
	/*
	 * Defer setting the usb_mux until HPD goes high, svdm_dp_attention().
	 * The AP only supports one DP phy. An external DP mux switches between
	 * the two ports. Should switch those muxes when it is really used,
	 * i.e. HPD high; otherwise, the real use case is preempted, like:
	 *  (1) plug a dongle without monitor connected to port-0,
	 *  (2) plug a dongle without monitor connected to port-1,
	 *  (3) plug a monitor to the port-1 dongle.
	 */

	payload[0] =
		VDO(USB_SID_DISPLAYPORT, 1, CMD_DP_CONFIG | VDO_OPOS(opos));
	payload[1] = VDO_DP_CFG(pin_mode, /* pin mode */
				1, /* DPv1.3 signaling */
				2); /* UFP connected */
	return 2;
};

__override void svdm_dp_post_config(int port)
{
	mux_state_t mux_mode = svdm_dp_get_mux_mode(port);

	typec_set_sbu(port, true);

	/*
	 * Prior to post-config, the mux will be reset to safe mode, and this
	 * will break mux config and aux path config we did in the first DP
	 * status command. Only enable this if the port is the current aux-port.
	 */
	if (port == active_aux_port) {
		usb_mux_set(port, mux_mode, USB_SWITCH_CONNECT,
			    polarity_rm_dts(pd_get_polarity(port)));
		usb_mux_hpd_update(port, USB_PD_MUX_HPD_LVL |
						 USB_PD_MUX_HPD_IRQ_DEASSERTED);
	}

	dp_flags[port] |= DP_FLAGS_DP_ON;
}

int corsola_is_dp_muxable(int port)
{
	int i;

	for (i = 0; i < board_get_usb_pd_port_count(); i++) {
		if (i != port) {
			if (usb_mux_get(i) & USB_PD_MUX_DP_ENABLED) {
				return 0;
			}
		}
	}

	return 1;
}

__override int svdm_dp_attention(int port, uint32_t *payload)
{
	int lvl = PD_VDO_DPSTS_HPD_LVL(payload[1]);
	int irq = PD_VDO_DPSTS_HPD_IRQ(payload[1]);
#ifdef CONFIG_USB_PD_DP_HPD_GPIO
	int cur_lvl = svdm_get_hpd_gpio(port);
#endif /* CONFIG_USB_PD_DP_HPD_GPIO */
	mux_state_t mux_state;

	dp_status[port] = payload[1];

	if (!corsola_is_dp_muxable(port)) {
		/* TODO(waihong): Info user? */
		CPRINTS("p%d: The other port is already muxed.", port);
		return 0; /* nak */
	}

	if (lvl) {
		set_dp_aux_path_sel(port);

		usb_mux_set(port, USB_PD_MUX_DOCK, USB_SWITCH_CONNECT,
			    polarity_rm_dts(pd_get_polarity(port)));
	} else {
		usb_mux_set(port, USB_PD_MUX_USB_ENABLED, USB_SWITCH_CONNECT,
			    polarity_rm_dts(pd_get_polarity(port)));
	}

	if (chipset_in_state(CHIPSET_STATE_ANY_SUSPEND) && (irq || lvl)) {
		/*
		 * Wake up the AP.  IRQ or level high indicates a DP sink is now
		 * present.
		 */
		if (IS_ENABLED(CONFIG_MKBP_EVENT)) {
			pd_notify_dp_alt_mode_entry(port);
		}
	}

#ifdef CONFIG_USB_PD_DP_HPD_GPIO
	if (irq && !lvl) {
		/*
		 * IRQ can only be generated when the level is high, because
		 * the IRQ is signaled by a short low pulse from the high level.
		 */
		CPRINTF("ERR:HPD:IRQ&LOW\n");
		return 0; /* nak */
	}

	if (irq && cur_lvl) {
		uint64_t now = get_time().val;
		/* wait for the minimum spacing between IRQ_HPD if needed */
		if (now < svdm_hpd_deadline[port]) {
			usleep(svdm_hpd_deadline[port] - now);
		}

		/* generate IRQ_HPD pulse */
		svdm_set_hpd_gpio(port, 0);
		/*
		 * b/171172053#comment14: since the HPD_DSTREAM_DEBOUNCE_IRQ is
		 * very short (500us), we can use udelay instead of usleep for
		 * more stable pulse period.
		 */
		udelay(HPD_DSTREAM_DEBOUNCE_IRQ);
		svdm_set_hpd_gpio(port, 1);
	} else {
		svdm_set_hpd_gpio(port, lvl);
	}

	/* set the minimum time delay (2ms) for the next HPD IRQ */
	svdm_hpd_deadline[port] = get_time().val + HPD_USTREAM_DEBOUNCE_LVL;
#endif /* CONFIG_USB_PD_DP_HPD_GPIO */

	mux_state = (lvl ? USB_PD_MUX_HPD_LVL : USB_PD_MUX_HPD_LVL_DEASSERTED) |
		    (irq ? USB_PD_MUX_HPD_IRQ : USB_PD_MUX_HPD_IRQ_DEASSERTED);
	usb_mux_hpd_update(port, mux_state);

#ifdef USB_PD_PORT_TCPC_MST
	if (port == USB_PD_PORT_TCPC_MST) {
		baseboard_mst_enable_control(port, lvl);
	}
#endif

	/* ack */
	return 1;
}
```

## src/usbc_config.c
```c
/* Copyright 2021 The ChromiumOS Authors
 * Use of this source code is governed by a BSD-style license that can be
 * found in the LICENSE file.
 */

/* Corsola baseboard-specific USB-C configuration */

#include <zephyr/drivers/gpio.h>
#include <ap_power/ap_power.h>

#include "adc.h"
#include "baseboard_usbc_config.h"
#include "button.h"
#include "charger.h"
#include "charge_state_v2.h"
#include "console.h"
#include "ec_commands.h"
#include "extpower.h"
#include "gpio/gpio_int.h"
#include "hooks.h"
#include "i2c.h"
#include "lid_switch.h"
#include "task.h"
#include "ppc/syv682x_public.h"
#include "power.h"
#include "power_button.h"
#include "spi.h"
#include "switch.h"
#include "tablet_mode.h"
#include "uart.h"
#include "usb_charge.h"
#include "usb_mux.h"
#include "usb_pd_tcpm.h"
#include "usb_tc_sm.h"
#include "usbc/usb_muxes.h"
#include "usbc_ppc.h"

#include "variant_db_detection.h"

#define CPRINTS(format, args...) cprints(CC_SYSTEM, format, ##args)
#define CPRINTF(format, args...) cprintf(CC_SYSTEM, format, ##args)

/* a flag for indicating the tasks are inited. */
static bool tasks_inited;

/* Baseboard */
static void baseboard_init(void)
{
#ifdef CONFIG_VARIANT_CORSOLA_USBA
	gpio_enable_dt_interrupt(GPIO_INT_FROM_NODELABEL(int_usba));
#endif
	/* If CCD mode has enabled before init, force the ccd_interrupt. */
	if (!gpio_pin_get_dt(GPIO_DT_FROM_NODELABEL(gpio_ccd_mode_odl))) {
		ccd_interrupt(GPIO_CCD_MODE_ODL);
	}
	gpio_enable_dt_interrupt(GPIO_INT_FROM_NODELABEL(int_ccd_mode_odl));
}
DECLARE_HOOK(HOOK_INIT, baseboard_init, HOOK_PRIO_PRE_DEFAULT);

__override uint8_t board_get_usb_pd_port_count(void)
{
	/* This function returns the PORT_COUNT+1 when HDMI db is connected.
	 * This is a trick to ensure the usb_mux_set being set properley.
	 * HDMI display functions using the USB virtual mux to * communicate
	 * with the DP bridge.
	 */
	if (corsola_get_db_type() == CORSOLA_DB_HDMI) {
		if (tasks_inited) {
			return CONFIG_USB_PD_PORT_MAX_COUNT;
		} else {
			return CONFIG_USB_PD_PORT_MAX_COUNT - 1;
		}
	} else if (corsola_get_db_type() == CORSOLA_DB_NONE) {
		return CONFIG_USB_PD_PORT_MAX_COUNT - 1;
	}

	return CONFIG_USB_PD_PORT_MAX_COUNT;
}

uint8_t board_get_adjusted_usb_pd_port_count(void)
{
	if (corsola_get_db_type() == CORSOLA_DB_TYPEC) {
		return CONFIG_USB_PD_PORT_MAX_COUNT;
	} else {
		return CONFIG_USB_PD_PORT_MAX_COUNT - 1;
	}
}

/* USB-A */
void usb_a0_interrupt(enum gpio_signal signal)
{
	enum usb_charge_mode mode = gpio_pin_get_dt(GPIO_DT_FROM_NODELABEL(
					    gpio_ap_xhci_init_done)) ?
					    USB_CHARGE_MODE_ENABLED :
					    USB_CHARGE_MODE_DISABLED;

	const int xhci_stat = gpio_get_level(signal);

	for (int i = 0; i < USB_PORT_COUNT; i++) {
		usb_charge_set_mode(i, mode, USB_ALLOW_SUSPEND_CHARGE);
	}

	for (int i = 0; i < CONFIG_USB_PD_PORT_MAX_COUNT; i++) {
		/*
		 * Enable DRP toggle after XHCI inited. This is used to follow
		 * USB 3.2 spec 10.3.1.1.
		 */
		if (xhci_stat) {
			pd_set_dual_role(i, PD_DRP_TOGGLE_ON);
		} else if (tc_is_attached_src(i)) {
			/*
			 * This is a AP reset S0->S0 transition.
			 * We should set the role back to sink.
			 */
			pd_set_dual_role(i, PD_DRP_FORCE_SINK);
		}
	}
}

__override enum pd_dual_role_states pd_get_drp_state_in_s0(void)
{
	if (gpio_pin_get_dt(GPIO_DT_FROM_NODELABEL(gpio_ap_xhci_init_done))) {
		return PD_DRP_TOGGLE_ON;
	} else {
		return PD_DRP_FORCE_SINK;
	}
}

void board_set_charge_limit(int port, int supplier, int charge_ma, int max_ma,
			    int charge_mv)
{
	charge_set_input_current_limit(
		MAX(charge_ma, CONFIG_CHARGER_INPUT_CURRENT), charge_mv);
}

void board_pd_vconn_ctrl(int port, enum usbpd_cc_pin cc_pin, int enabled)
{
	/*
	 * We ignore the cc_pin and PPC vconn because polarity and PPC vconn
	 * should already be set correctly in the PPC driver via the pd
	 * state machine.
	 */
}

/* HDMI/TYPE-C function shared subboard interrupt */
void x_ec_interrupt(enum gpio_signal signal)
{
	int sub = corsola_get_db_type();

	if (sub == CORSOLA_DB_TYPEC) {
		/* C1: PPC interrupt */
		ppc_interrupt(signal);
	} else if (sub == CORSOLA_DB_HDMI) {
		hdmi_hpd_interrupt(signal);
	} else {
		CPRINTS("Undetected subboard interrupt.");
	}
}

static void board_hdmi_handler(struct ap_power_ev_callback *cb,
			       struct ap_power_ev_data data)
{
	int value;

	switch (data.event) {
	default:
		return;

	case AP_POWER_RESUME:
		value = 1;
		break;

	case AP_POWER_SUSPEND:
		value = 0;
		break;
	}
	gpio_pin_set_dt(GPIO_DT_FROM_ALIAS(gpio_en_hdmi_pwr), value);
	gpio_pin_set_dt(GPIO_DT_FROM_ALIAS(gpio_ps185_pwrdn_odl), value);
}

static void tasks_init_deferred(void)
{
	tasks_inited = true;
	if (corsola_get_db_type() == CORSOLA_DB_HDMI) {
		/* If the HDMI port is plugged on-boot, and the usb_mux won't
		 * be configured before the task inited.  Re-invoke the
		 * HPD configuration after task inited.
		 */
		ps185_hdmi_hpd_mux_set();
	}
}
DECLARE_DEFERRED(tasks_init_deferred);

static void baseboard_x_ec_gpio2_init(void)
{
	static struct ppc_drv virtual_ppc_drv = { 0 };
	static struct tcpm_drv virtual_tcpc_drv = { 0 };
	static struct bc12_drv virtual_bc12_drv = { 0 };

	/* no sub board */
	if (corsola_get_db_type() == CORSOLA_DB_NONE) {
		return;
	}

	/* type-c: USB_C1_PPC_INT_ODL / hdmi: PS185_EC_DP_HPD */
	gpio_enable_dt_interrupt(GPIO_INT_FROM_NODELABEL(int_x_ec_gpio2));

	if (corsola_get_db_type() == CORSOLA_DB_TYPEC) {
		gpio_pin_interrupt_configure_dt(
			GPIO_DT_FROM_ALIAS(gpio_usb_c1_ppc_int_odl),
			GPIO_INT_EDGE_FALLING);
		return;
	}
	if (corsola_get_db_type() == CORSOLA_DB_HDMI) {
		static struct ap_power_ev_callback cb;

		ap_power_ev_init_callback(&cb, board_hdmi_handler,
					  AP_POWER_RESUME | AP_POWER_SUSPEND);
		ap_power_ev_add_callback(&cb);
	}

	/* drop related C1 port drivers when it's a HDMI DB. */
	ppc_chips[USBC_PORT_C1] =
		(const struct ppc_config_t){ .drv = &virtual_ppc_drv };
	tcpc_config[USBC_PORT_C1] =
		(const struct tcpc_config_t){ .drv = &virtual_tcpc_drv };
	bc12_ports[USBC_PORT_C1] =
		(const struct bc12_config){ .drv = &virtual_bc12_drv };
	/* Use virtual mux to notify AP the mainlink direction. */
	USB_MUX_ENABLE_ALTERNATIVE(usb_mux_chain_1_hdmi_db);

	/*
	 * If a HDMI DB is attached, C1 port tasks will be exiting in that
	 * the port number is larger than board_get_usb_pd_port_count().
	 * After C1 port tasks finished, we intentionally increase the port
	 * count by 1 for usb_mux to access the C1 virtual mux for notifying
	 * mainlink direction.
	 */
	hook_call_deferred(&tasks_init_deferred_data, 2 * SECOND);
}
DECLARE_HOOK(HOOK_INIT, baseboard_x_ec_gpio2_init, HOOK_PRIO_DEFAULT);

__override uint8_t get_dp_pin_mode(int port)
{
	if (corsola_get_db_type() == CORSOLA_DB_HDMI && port == USBC_PORT_C1) {
		if (usb_mux_get(USBC_PORT_C1) & USB_PD_MUX_DP_ENABLED) {
			return MODE_DP_PIN_E;
		} else {
			return 0;
		}
	}

	return pd_dfp_dp_get_pin_mode(port, dp_status[port]);
}
```

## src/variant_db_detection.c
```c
/* Copyright 2021 The ChromiumOS Authors
 * Use of this source code is governed by a BSD-style license that can be
 * found in the LICENSE file.
 */

/* Corsola daughter board detection */
#include <zephyr/drivers/gpio.h>

#include "baseboard_usbc_config.h"
#include "console.h"
#include "cros_cbi.h"
#include "gpio/gpio_int.h"
#include "hooks.h"
#include "usb_mux.h"

#include "variant_db_detection.h"

#define CPRINTS(format, args...) cprints(CC_SYSTEM, format, ##args)
#define CPRINTF(format, args...) cprintf(CC_SYSTEM, format, ##args)

#ifdef TEST_BUILD
uint32_t dp_status[CONFIG_USB_PD_PORT_MAX_COUNT];
#endif

static void corsola_db_config(enum corsola_db_type type)
{
	switch (type) {
	case CORSOLA_DB_HDMI:
		/* EC_X_GPIO1 */
		gpio_pin_configure_dt(GPIO_DT_FROM_ALIAS(gpio_en_hdmi_pwr),
				      GPIO_OUTPUT_HIGH);
		/* X_EC_GPIO2 */
		gpio_pin_configure_dt(GPIO_DT_FROM_ALIAS(gpio_ps185_ec_dp_hpd),
				      GPIO_INPUT);
		gpio_enable_dt_interrupt(
			GPIO_INT_FROM_NODELABEL(int_x_ec_gpio2));
		/* EC_X_GPIO3 */
		gpio_pin_configure_dt(GPIO_DT_FROM_ALIAS(gpio_ps185_pwrdn_odl),
				      GPIO_OUTPUT_HIGH | GPIO_OPEN_DRAIN);
		return;
	case CORSOLA_DB_TYPEC:
		/* EC_X_GPIO1 */
		gpio_pin_configure_dt(GPIO_DT_FROM_ALIAS(gpio_usb_c1_frs_en),
				      GPIO_OUTPUT_LOW);
		/* X_EC_GPIO2 */
		gpio_pin_configure_dt(
			GPIO_DT_FROM_ALIAS(gpio_usb_c1_ppc_int_odl),
			GPIO_INPUT | GPIO_PULL_UP);
		gpio_enable_dt_interrupt(
			GPIO_INT_FROM_NODELABEL(int_x_ec_gpio2));
		/* EC_X_GPIO3 */
		gpio_pin_configure_dt(GPIO_DT_FROM_ALIAS(gpio_usb_c1_dp_in_hpd),
				      GPIO_OUTPUT_LOW);
		return;
	case CORSOLA_DB_NONE:
		/* Set floating pins as input with PU to prevent leakage */
		gpio_pin_configure_dt(GPIO_DT_FROM_NODELABEL(gpio_ec_x_gpio1),
				      GPIO_INPUT | GPIO_PULL_UP);
		gpio_pin_configure_dt(GPIO_DT_FROM_NODELABEL(gpio_x_ec_gpio2),
				      GPIO_INPUT | GPIO_PULL_UP);
		gpio_pin_configure_dt(GPIO_DT_FROM_NODELABEL(gpio_ec_x_gpio3),
				      GPIO_INPUT | GPIO_PULL_UP);
		return;
	default:
		break;
	}
}

enum corsola_db_type corsola_get_db_type(void)
{
#if DT_NODE_EXISTS(DT_NODELABEL(db_config))
	int ret;
	uint32_t val;
#endif
	static enum corsola_db_type db = CORSOLA_DB_UNINIT;

	if (db != CORSOLA_DB_UNINIT) {
		return db;
	}

	if (!gpio_pin_get_dt(GPIO_DT_FROM_NODELABEL(gpio_hdmi_prsnt_odl))) {
		db = CORSOLA_DB_HDMI;
	} else {
		db = CORSOLA_DB_TYPEC;
	}

/* Detect for no sub board case by FW_CONFIG */
#if DT_NODE_EXISTS(DT_NODELABEL(db_config))
	ret = cros_cbi_get_fw_config(DB, &val);
	if (ret != 0) {
		CPRINTS("Error retrieving CBI FW_CONFIG field %d", DB);
	} else if (val == DB_NONE) {
		db = CORSOLA_DB_NONE;
	}
#endif

	corsola_db_config(db);

	switch (db) {
	case CORSOLA_DB_NONE:
		CPRINTS("Detect %s DB", "NONE");
		break;
	case CORSOLA_DB_TYPEC:
		CPRINTS("Detect %s DB", "TYPEC");
		break;
	case CORSOLA_DB_HDMI:
		CPRINTS("Detect %s DB", "HDMI");
		break;
	default:
		CPRINTS("DB UNINIT");
		break;
	}

	return db;
}

static void corsola_db_init(void)
{
	corsola_get_db_type();
}
DECLARE_HOOK(HOOK_INIT, corsola_db_init, HOOK_PRIO_PRE_I2C);

/**
 * Handle PS185 HPD changing state.
 */
void ps185_hdmi_hpd_mux_set(void)
{
	const int hpd =
		gpio_pin_get_dt(GPIO_DT_FROM_ALIAS(gpio_ps185_ec_dp_hpd));

	if (!corsola_is_dp_muxable(USBC_PORT_C1)) {
		return;
	}

	if (hpd && !(usb_mux_get(USBC_PORT_C1) & USB_PD_MUX_DP_ENABLED)) {
		dp_status[USBC_PORT_C1] =
			VDO_DP_STATUS(0, /* HPD IRQ  ... not applicable */
				      0, /* HPD level ... not applicable */
				      0, /* exit DP? ... no */
				      0, /* usb mode? ... no */
				      0, /* multi-function ... no */
				      1, /* DP enabled ... yes */
				      0, /* power low?  ... no */
				      (!!DP_FLAGS_DP_ON));
		/* update C1 virtual mux */
		usb_mux_set(USBC_PORT_C1, USB_PD_MUX_DP_ENABLED,
			    USB_SWITCH_DISCONNECT,
			    0 /* polarity, don't care */);
		CPRINTS("HDMI plug");
	}
}

static void ps185_hdmi_hpd_deferred(void)
{
	const int hpd =
		gpio_pin_get_dt(GPIO_DT_FROM_ALIAS(gpio_ps185_ec_dp_hpd));

	if (!hpd && (usb_mux_get(USBC_PORT_C1) & USB_PD_MUX_DP_ENABLED)) {
		dp_status[USBC_PORT_C1] =
			VDO_DP_STATUS(0, /* HPD IRQ  ... not applicable */
				      0, /* HPD level ... not applicable */
				      0, /* exit DP? ... no */
				      0, /* usb mode? ... no */
				      0, /* multi-function ... no */
				      0, /* DP enabled ... no */
				      0, /* power low?  ... no */
				      (!DP_FLAGS_DP_ON));
		usb_mux_set(USBC_PORT_C1, USB_PD_MUX_NONE,
			    USB_SWITCH_DISCONNECT,
			    0 /* polarity, don't care */);
		CPRINTS("HDMI unplug");

		return;
	}

	ps185_hdmi_hpd_mux_set();
}
DECLARE_DEFERRED(ps185_hdmi_hpd_deferred);

#define HPD_SINK_ABSENCE_DEBOUNCE (2 * MSEC)

void hdmi_hpd_interrupt(enum gpio_signal signal)
{
	const int hpd =
		gpio_pin_get_dt(GPIO_DT_FROM_ALIAS(gpio_ps185_ec_dp_hpd));

	if (!hpd) {
		hook_call_deferred(&ps185_hdmi_hpd_deferred_data,
				   HPD_SINK_ABSENCE_DEBOUNCE);
	} else {
		hook_call_deferred(&ps185_hdmi_hpd_deferred_data, -1);
	}

	/* C0 DP is muxed, we should not send HPD to the AP */
	if (!corsola_is_dp_muxable(USBC_PORT_C1)) {
		if (hpd) {
			CPRINTS("C0 port is already muxed.");
		}
		return;
	}

	if (hpd && !(usb_mux_get(USBC_PORT_C1) & USB_PD_MUX_DP_ENABLED)) {
		/* set dp_aux_path_sel first, and configure the usb_mux in the
		 * deferred hook to prevent from dead locking.
		 */
		gpio_pin_set_dt(GPIO_DT_FROM_NODELABEL(dp_aux_path_sel), hpd);
		hook_call_deferred(&ps185_hdmi_hpd_deferred_data, 0);
	}

	svdm_set_hpd_gpio(USBC_PORT_C1, hpd);
}
```
